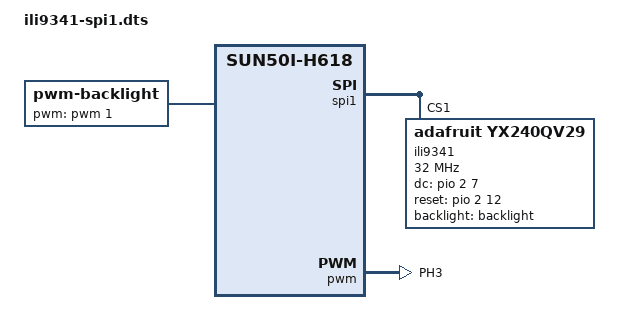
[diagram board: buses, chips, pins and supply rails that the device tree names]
/dts-v1/;
/plugin/;

/ {
	compatible = "allwinner,sun50i-h616", "allwinner,sun50i-h618";

	fragment@0 {
		target = <&spi1>;
		__overlay__ {
			#address-cells = <1>;
			#size-cells = <0>;
			status = "okay";

			/delete-node/ spidev@1;

			ili9341: ili9341@1 {
				compatible = "adafruit,yx240qv29";
				reg = <1>;
				spi-max-frequency = <32000000>;
				rotation = <90>;
				/*
				 * Wiring (20-pin header):
				 *   DC/RS  → pin 14 = GPIO_PC7  = port C (2), pin 7
				 *   RESET  → pin 12 = GPIO_PC12 = port C (2), pin 12
				 *
				 * &pio bank: A=0 B=1 C=2 D=3 E=4 F=5 G=6 H=7
				 */
				dc-gpios = <&pio 2 7 0>;
				reset-gpios = <&pio 2 12 0>;
				backlight = <&backlight>;
			};
		};
	};

	fragment@1 {
		target-path = "/";
		__overlay__ {
			backlight: backlight {
				compatible = "pwm-backlight";
				pwms = <&pwm 1 1000000 0>;
				brightness-levels = <0 16 32 64 128 192 255>;
				default-brightness-level = <6>;
			};
		};
	};

	fragment@2 {
		target = <&pwm>;
		__overlay__ {
			pinctrl-names = "default";
			pinctrl-0 = <&pwm1_ph_pin>;
			status = "okay";
		};
	};

	fragment@3 {
		target = <&pio>;
		__overlay__ {
			pwm1_ph_pin: pwm1-ph-pin {
				pins = "PH3";
				function = "pwm1";
			};
		};
	};
};
